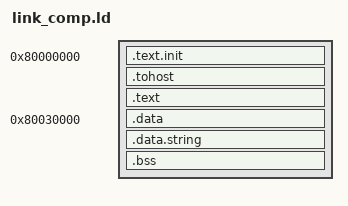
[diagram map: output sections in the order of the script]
OUTPUT_ARCH( "riscv" )
ENTRY(_start)

SECTIONS
{
  . = 0x80000000;
  .text.init : { *(.text.init) }
  . = ALIGN(0x1000);
  .tohost : { *(.tohost) }
  . = ALIGN(0x1000);
  .text : { *(.text) }
  . = ALIGN(0x1000);
  /*  . = 0x80000;*/
  . = 0x80030000;
  .data : { *(.data) }
  .data.string : { *(.data.string)}
  .bss : { *(.bss) }
  _end = .;
}

